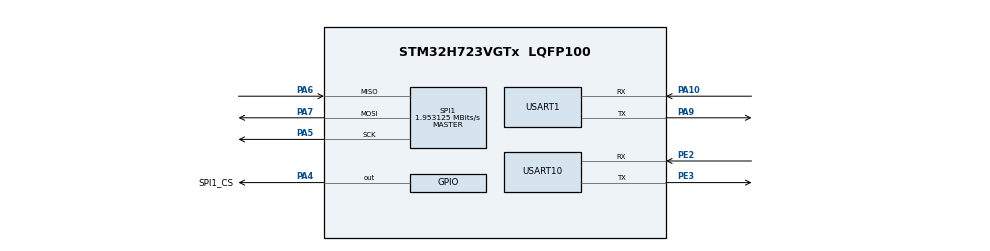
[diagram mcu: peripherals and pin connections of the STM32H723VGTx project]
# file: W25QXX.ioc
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CORTEX_M7.default_mode_Activation=1
Dma.Request0=SPI1_TX
Dma.Request1=SPI1_RX
Dma.SPI1_RX.1.Direction=DMA_PERIPH_TO_MEMORY
Dma.SPI1_RX.1.EventEnable=DISABLE
Dma.SPI1_RX.1.FIFOMode=DMA_FIFOMODE_DISABLE
Dma.SPI1_RX.1.Instance=DMA1_Stream1
Dma.SPI1_RX.1.MemDataAlignment=DMA_MDATAALIGN_BYTE
Dma.SPI1_RX.1.MemInc=DMA_MINC_ENABLE
Dma.SPI1_RX.1.Mode=DMA_NORMAL
Dma.SPI1_RX.1.PeriphDataAlignment=DMA_PDATAALIGN_BYTE
Dma.SPI1_RX.1.PeriphInc=DMA_PINC_DISABLE
Dma.SPI1_RX.1.Polarity=HAL_DMAMUX_REQ_GEN_RISING
Dma.SPI1_RX.1.Priority=DMA_PRIORITY_LOW
Dma.SPI1_RX.1.RequestNumber=1
Dma.SPI1_RX.1.SignalID=NONE
Dma.SPI1_RX.1.SyncEnable=DISABLE
Dma.SPI1_RX.1.SyncPolarity=HAL_DMAMUX_SYNC_NO_EVENT
Dma.SPI1_RX.1.SyncRequestNumber=1
Dma.SPI1_RX.1.SyncSignalID=NONE
Dma.SPI1_TX.0.Direction=DMA_MEMORY_TO_PERIPH
Dma.SPI1_TX.0.EventEnable=DISABLE
Dma.SPI1_TX.0.FIFOMode=DMA_FIFOMODE_DISABLE
Dma.SPI1_TX.0.Instance=DMA1_Stream0
Dma.SPI1_TX.0.MemDataAlignment=DMA_MDATAALIGN_BYTE
Dma.SPI1_TX.0.MemInc=DMA_MINC_ENABLE
Dma.SPI1_TX.0.Mode=DMA_NORMAL
Dma.SPI1_TX.0.PeriphDataAlignment=DMA_PDATAALIGN_BYTE
Dma.SPI1_TX.0.PeriphInc=DMA_PINC_DISABLE
Dma.SPI1_TX.0.Polarity=HAL_DMAMUX_REQ_GEN_RISING
Dma.SPI1_TX.0.Priority=DMA_PRIORITY_LOW
Dma.SPI1_TX.0.RequestNumber=1
Dma.SPI1_TX.0.SignalID=NONE
Dma.SPI1_TX.0.SyncEnable=DISABLE
Dma.SPI1_TX.0.SyncPolarity=HAL_DMAMUX_SYNC_NO_EVENT
Dma.SPI1_TX.0.SyncRequestNumber=1
Dma.SPI1_TX.0.SyncSignalID=NONE
Mcu.Family=STM32H7
Mcu.Name=STM32H723VGTx
Mcu.Package=LQFP100
NVIC.DMA1_Stream0_IRQn=true\:0\:0\:false\:false\:true\:false\:true\:true
NVIC.DMA1_Stream1_IRQn=true\:0\:0\:false\:false\:true\:false\:true\:true
NVIC.PriorityGroup=NVIC_PRIORITYGROUP_4
NVIC.SPI1_IRQn=true\:0\:0\:false\:false\:true\:true\:true\:true
NVIC.USART10_IRQn=true\:0\:0\:false\:false\:true\:true\:true\:true
NVIC.USART1_IRQn=true\:0\:0\:false\:false\:true\:true\:true\:true
PA10.Mode=Asynchronous
PA10.Signal=USART1_RX
PA13(JTMS/SWDIO).Mode=Serial_Wire
PA13(JTMS/SWDIO).Signal=DEBUG_JTMS-SWDIO
PA14(JTCK/SWCLK).Mode=Serial_Wire
PA14(JTCK/SWCLK).Signal=DEBUG_JTCK-SWCLK
PA4.GPIO_Label=SPI1_CS
PA4.GPIO_PuPd=GPIO_PULLUP
PA4.GPIO_Speed=GPIO_SPEED_FREQ_HIGH
PA4.PinState=GPIO_PIN_SET
PA4.Signal=GPIO_Output
PA5.GPIO_PuPd=GPIO_PULLDOWN
PA5.GPIO_Speed=GPIO_SPEED_FREQ_HIGH
PA5.Mode=Full_Duplex_Master
PA5.Signal=SPI1_SCK
PA6.GPIO_PuPd=GPIO_PULLUP
PA6.GPIO_Speed=GPIO_SPEED_FREQ_HIGH
PA6.Mode=Full_Duplex_Master
PA6.Signal=SPI1_MISO
PA7.GPIO_PuPd=GPIO_PULLUP
PA7.GPIO_Speed=GPIO_SPEED_FREQ_HIGH
PA7.Mode=Full_Duplex_Master
PA7.Signal=SPI1_MOSI
PA9.Mode=Asynchronous
PA9.Signal=USART1_TX
PE2.Mode=Asynchronous
PE2.Signal=USART10_RX
PE3.Mode=Asynchronous
PE3.Signal=USART10_TX
PH0-OSC_IN.Mode=HSE-External-Oscillator
PH0-OSC_IN.Signal=RCC_OSC_IN
PH1-OSC_OUT.Mode=HSE-External-Oscillator
PH1-OSC_OUT.Signal=RCC_OSC_OUT
ProjectManager.HeapSize=0x200
ProjectManager.StackSize=0x400
ProjectManager.TargetToolchain=MDK-ARM V5.32
RCC.ADCFreq_Value=50390625
RCC.APB1Freq_Value=62500000
RCC.APB2Freq_Value=31250000
RCC.APB3Freq_Value=62500000
RCC.APB4Freq_Value=62500000
RCC.CortexFreq_Value=125000000
RCC.D1CPRE=RCC_SYSCLK_DIV2
RCC.D1PPRE=RCC_APB3_DIV2
RCC.D2PPRE1=RCC_APB1_DIV2
RCC.D2PPRE2=RCC_APB2_DIV4
RCC.D3PPRE=RCC_APB4_DIV2
RCC.DIVM1=4
RCC.DIVN1=40
RCC.DIVP1=1
RCC.DIVQ1=4
RCC.HCLKFreq_Value=125000000
RCC.PLL2FRACN=0
RCC.PLL3FRACN=0
RCC.PLLFRACN=0
RCC.PLLSourceVirtual=RCC_PLLSOURCE_HSE
RCC.SYSCLKFreq_VALUE=250000000
RCC.SYSCLKSource=RCC_SYSCLKSOURCE_PLLCLK
RCC.USBFreq_Value=62500000
SPI1.BaudRatePrescaler=SPI_BAUDRATEPRESCALER_32
SPI1.CalculateBaudRate=1.953125 MBits/s
SPI1.DataSize=SPI_DATASIZE_8BIT
SPI1.Direction=SPI_DIRECTION_2LINES
SPI1.MasterKeepIOState=SPI_MASTER_KEEP_IO_STATE_ENABLE
SPI1.Mode=SPI_MODE_MASTER
SPI1.NSSPMode=SPI_NSS_PULSE_DISABLE
SPI1.VirtualType=VM_MASTER
USART1.VirtualMode-Asynchronous=VM_ASYNC
USART10.VirtualMode=VM_ASYNC
VP_MEMORYMAP_VS_MEMORYMAP.Mode=CurAppReg
board=custom

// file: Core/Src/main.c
/* USER CODE BEGIN Header */
/**
  ******************************************************************************
  * @file           : main.c
  * @brief          : Main program body
  ******************************************************************************
  * @attention
  *
  * Copyright (c) 2026 STMicroelectronics.
  * All rights reserved.
  *
  * This software is licensed under terms that can be found in the LICENSE file
  * in the root directory of this software component.
  * If no LICENSE file comes with this software, it is provided AS-IS.
  *
  ******************************************************************************
  */
/* USER CODE END Header */
#include "main.h"
#include "dma.h"
#include "spi.h"
#include "usart.h"
#include "gpio.h"

/* USER CODE BEGIN Includes */
#include "user_main.h"
/* USER CODE END Includes */

void SystemClock_Config(void);
static void MPU_Config(void);

int main(void)
{

  /* MPU Configuration--------------------------------------------------------*/
  MPU_Config();

  /* MCU Configuration--------------------------------------------------------*/

  /* Reset of all peripherals, Initializes the Flash interface and the Systick. */
  HAL_Init();

  /* Configure the system clock */
  SystemClock_Config();

  /* Initialize all configured peripherals */
  MX_GPIO_Init();
  MX_DMA_Init();
  MX_SPI1_Init();
  MX_USART1_UART_Init();
  MX_USART10_UART_Init();
  /* USER CODE BEGIN 2 */
  init();
  /* USER CODE END 2 */

  /* Infinite loop */
  while (1)
  {

    /* USER CODE BEGIN 3 */
    loop();
  }
  /* USER CODE END 3 */
}

void SystemClock_Config(void)
{
  RCC_OscInitTypeDef RCC_OscInitStruct = {0};
  RCC_ClkInitTypeDef RCC_ClkInitStruct = {0};

  /** Supply configuration update enable
  */
  HAL_PWREx_ConfigSupply(PWR_LDO_SUPPLY);

  /** Configure the main internal regulator output voltage
  */
  __HAL_PWR_VOLTAGESCALING_CONFIG(PWR_REGULATOR_VOLTAGE_SCALE2);

  while(!__HAL_PWR_GET_FLAG(PWR_FLAG_VOSRDY)) {}

  /** Initializes the RCC Oscillators according to the specified parameters
  * in the RCC_OscInitTypeDef structure.
  */
  RCC_OscInitStruct.OscillatorType = RCC_OSCILLATORTYPE_HSE;
  RCC_OscInitStruct.HSEState = RCC_HSE_ON;
  RCC_OscInitStruct.PLL.PLLState = RCC_PLL_ON;
  RCC_OscInitStruct.PLL.PLLSource = RCC_PLLSOURCE_HSE;
  RCC_OscInitStruct.PLL.PLLM = 4;
  RCC_OscInitStruct.PLL.PLLN = 40;
  RCC_OscInitStruct.PLL.PLLP = 1;
  RCC_OscInitStruct.PLL.PLLQ = 4;
  RCC_OscInitStruct.PLL.PLLR = 2;
  RCC_OscInitStruct.PLL.PLLRGE = RCC_PLL1VCIRANGE_2;
  RCC_OscInitStruct.PLL.PLLVCOSEL = RCC_PLL1VCOWIDE;
  RCC_OscInitStruct.PLL.PLLFRACN = 0;
  if (HAL_RCC_OscConfig(&RCC_OscInitStruct) != HAL_OK)
  {
    Error_Handler();
  }

  /** Initializes the CPU, AHB and APB buses clocks
  */
  RCC_ClkInitStruct.ClockType = RCC_CLOCKTYPE_HCLK|RCC_CLOCKTYPE_SYSCLK
                              |RCC_CLOCKTYPE_PCLK1|RCC_CLOCKTYPE_PCLK2
                              |RCC_CLOCKTYPE_D3PCLK1|RCC_CLOCKTYPE_D1PCLK1;
  RCC_ClkInitStruct.SYSCLKSource = RCC_SYSCLKSOURCE_PLLCLK;
  RCC_ClkInitStruct.SYSCLKDivider = RCC_SYSCLK_DIV2;
  RCC_ClkInitStruct.AHBCLKDivider = RCC_HCLK_DIV1;
  RCC_ClkInitStruct.APB3CLKDivider = RCC_APB3_DIV2;
  RCC_ClkInitStruct.APB1CLKDivider = RCC_APB1_DIV2;
  RCC_ClkInitStruct.APB2CLKDivider = RCC_APB2_DIV4;
  RCC_ClkInitStruct.APB4CLKDivider = RCC_APB4_DIV2;

  if (HAL_RCC_ClockConfig(&RCC_ClkInitStruct, FLASH_LATENCY_2) != HAL_OK)
  {
    Error_Handler();
  }
}

 /* MPU Configuration */

void MPU_Config(void)
{
  MPU_Region_InitTypeDef MPU_InitStruct = {0};

  /* Disables the MPU */
  HAL_MPU_Disable();

  /** Initializes and configures the Region and the memory to be protected
  */
  MPU_InitStruct.Enable = MPU_REGION_ENABLE;
  MPU_InitStruct.Number = MPU_REGION_NUMBER0;
  MPU_InitStruct.BaseAddress = 0x0;
  MPU_InitStruct.Size = MPU_REGION_SIZE_4GB;
  MPU_InitStruct.SubRegionDisable = 0x87;
  MPU_InitStruct.TypeExtField = MPU_TEX_LEVEL0;
  MPU_InitStruct.AccessPermission = MPU_REGION_NO_ACCESS;
  MPU_InitStruct.DisableExec = MPU_INSTRUCTION_ACCESS_DISABLE;
  MPU_InitStruct.IsShareable = MPU_ACCESS_SHAREABLE;
  MPU_InitStruct.IsCacheable = MPU_ACCESS_NOT_CACHEABLE;
  MPU_InitStruct.IsBufferable = MPU_ACCESS_NOT_BUFFERABLE;

  HAL_MPU_ConfigRegion(&MPU_InitStruct);
  /* Enables the MPU */
  HAL_MPU_Enable(MPU_PRIVILEGED_DEFAULT);

}

void Error_Handler(void)
{
  __disable_irq();
  while (1)
  {
  }
}
